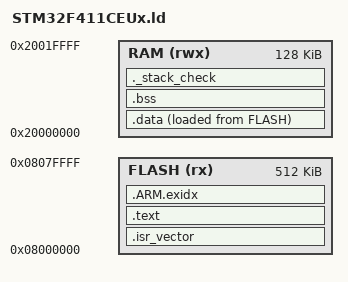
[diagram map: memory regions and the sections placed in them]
/* STM32F411CE: 512 KB de flash, 128 KB de RAM */
ENTRY(Reset_Handler)

MEMORY
{
  FLASH (rx)  : ORIGIN = 0x08000000, LENGTH = 512K
  RAM   (rwx) : ORIGIN = 0x20000000, LENGTH = 128K
}

_estack = ORIGIN(RAM) + LENGTH(RAM);
_Min_Stack_Size = 0x800;

SECTIONS
{
  .isr_vector : { KEEP(*(.isr_vector)) } > FLASH

  .text : {
    *(.text*) *(.rodata*)
    KEEP(*(.init)) KEEP(*(.fini))
    . = ALIGN(4);
  } > FLASH

  .ARM.exidx : { *(.ARM.exidx*) } > FLASH

  _sidata = LOADADDR(.data);
  .data : {
    . = ALIGN(4);
    _sdata = .;
    *(.data*)
    . = ALIGN(4);
    _edata = .;
  } > RAM AT > FLASH

  .bss (NOLOAD) : {
    . = ALIGN(4);
    _sbss = .;
    *(.bss*) *(COMMON)
    . = ALIGN(4);
    _ebss = .;
    end = .;
  } > RAM

  ._stack_check (NOLOAD) : {
    . = . + _Min_Stack_Size;
  } > RAM
}
